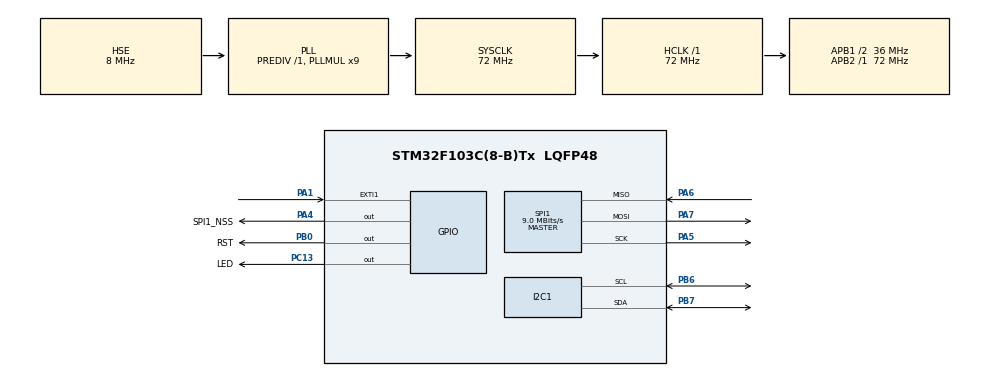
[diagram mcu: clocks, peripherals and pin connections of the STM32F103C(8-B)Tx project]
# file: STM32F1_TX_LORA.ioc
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Mcu.Family=STM32F1
Mcu.Name=STM32F103C(8-B)Tx
Mcu.Package=LQFP48
NVIC.EXTI1_IRQn=true\:0\:0\:false\:false\:true\:true\:true\:true
NVIC.PriorityGroup=NVIC_PRIORITYGROUP_4
PA1.GPIO_PuPd=GPIO_PULLUP
PA1.Signal=GPXTI1
PA13.Mode=Serial_Wire
PA13.Signal=SYS_JTMS-SWDIO
PA14.Mode=Serial_Wire
PA14.Signal=SYS_JTCK-SWCLK
PA4.GPIO_Label=SPI1_NSS
PA4.GPIO_PuPd=GPIO_NOPULL
PA4.PinState=GPIO_PIN_RESET
PA4.Signal=GPIO_Output
PA5.Mode=Full_Duplex_Master
PA5.Signal=SPI1_SCK
PA6.Mode=Full_Duplex_Master
PA6.Signal=SPI1_MISO
PA7.Mode=Full_Duplex_Master
PA7.Signal=SPI1_MOSI
PB0.GPIO_Label=RST
PB0.GPIO_PuPd=GPIO_NOPULL
PB0.PinState=GPIO_PIN_RESET
PB0.Signal=GPIO_Output
PB6.Mode=I2C
PB6.Signal=I2C1_SCL
PB7.Mode=I2C
PB7.Signal=I2C1_SDA
PC13-TAMPER-RTC.GPIO_Label=LED
PC13-TAMPER-RTC.GPIO_PuPd=GPIO_PULLUP
PC13-TAMPER-RTC.Signal=GPIO_Output
PD0-OSC_IN.Mode=HSE-External-Oscillator
PD0-OSC_IN.Signal=RCC_OSC_IN
PD1-OSC_OUT.Mode=HSE-External-Oscillator
PD1-OSC_OUT.Signal=RCC_OSC_OUT
ProjectManager.HeapSize=0x200
ProjectManager.StackSize=0x400
ProjectManager.TargetToolchain=STM32CubeIDE
RCC.AHBFreq_Value=72000000
RCC.APB1CLKDivider=RCC_HCLK_DIV2
RCC.APB1Freq_Value=36000000
RCC.APB1TimFreq_Value=72000000
RCC.APB2Freq_Value=72000000
RCC.APB2TimFreq_Value=72000000
RCC.HCLKFreq_Value=72000000
RCC.PLLMUL=RCC_PLL_MUL9
RCC.PLLSourceVirtual=RCC_PLLSOURCE_HSE
RCC.SYSCLKFreq_VALUE=72000000
RCC.SYSCLKSource=RCC_SYSCLKSOURCE_PLLCLK
RCC.USBFreq_Value=72000000
SPI1.BaudRatePrescaler=SPI_BAUDRATEPRESCALER_8
SPI1.CalculateBaudRate=9.0 MBits/s
SPI1.Direction=SPI_DIRECTION_2LINES
SPI1.Mode=SPI_MODE_MASTER
SPI1.VirtualType=VM_MASTER
board=custom

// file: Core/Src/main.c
/* USER CODE BEGIN Header */
/**
  ******************************************************************************
  * @file           : main.c
  * @brief          : Main program body
  ******************************************************************************
  * @attention
  *
  * Copyright (c) 2026 STMicroelectronics.
  * All rights reserved.
  *
  * This software is licensed under terms that can be found in the LICENSE file
  * in the root directory of this software component.
  * If no LICENSE file comes with this software, it is provided AS-IS.
  *
  ******************************************************************************
  */
/* USER CODE END Header */
#include <stdio.h>
#include <string.h>

#include "main.h"
#include "i2c-lcd.h"
#include "LoRa.h"

I2C_HandleTypeDef hi2c1;

SPI_HandleTypeDef hspi1;

/* USER CODE BEGIN PV */

LoRa myLoRa;
uint32_t last_send_tick = 0;
uint32_t send_count = 0;

/* USER CODE END PV */

void SystemClock_Config(void);
static void MX_GPIO_Init(void);
static void MX_SPI1_Init(void);
static void MX_I2C1_Init(void);

int main(void)
{

  /* MCU Configuration--------------------------------------------------------*/

  /* Reset of all peripherals, Initializes the Flash interface and the Systick. */
  HAL_Init();

  /* Configure the system clock */
  SystemClock_Config();

  /* Initialize all configured peripherals */
  MX_GPIO_Init();
  MX_SPI1_Init();
  MX_I2C1_Init();

  lcd_init();

  /* Dòng 1 LCD: tiêu đề cố định */
  lcd_goto_XY(1, 0);
  lcd_send_string("===== TX_LORA =====");

  /* USER CODE BEGIN 2 */

  myLoRa = newLoRa();
  myLoRa.hSPIx                 = &hspi1;
  myLoRa.CS_port               = NSS_GPIO_Port;
  myLoRa.CS_pin                = NSS_Pin;
  myLoRa.reset_port            = RST_GPIO_Port;
  myLoRa.reset_pin             = RST_Pin;
  myLoRa.DIO0_port             = DIO0_GPIO_Port;
  myLoRa.DIO0_pin              = DIO0_Pin;

  myLoRa.frequency             = 433;
  myLoRa.spredingFactor        = SF_7;
  myLoRa.bandWidth             = BW_125KHz;
  myLoRa.crcRate               = CR_4_5;
  myLoRa.power                 = POWER_20db;          // Công suất max
  myLoRa.overCurrentProtection = 120;
  myLoRa.preamble              = 10;

  /* Reset phần cứng module LoRa */
  LoRa_reset(&myLoRa);

  /* Khởi tạo LoRa, hiển thị trạng thái lên dòng 2 LCD */
  lcd_goto_XY(2, 0);
  while (LoRa_init(&myLoRa) != LORA_OK)
  {
    lcd_send_string("LoRa INIT FAIL!   ");
  }
  lcd_send_string("LoRa INIT OK! ");
  LoRa_setSyncWord(&myLoRa, 0x12); // Đảm bảo SyncWord của 2 mạch giống hệt nhau

  // Bật AGC
  LoRa_write(&myLoRa, 0x26, 0x04);

  /* USER CODE END 2 */

  /* Infinite loop */
  while (1)
  {
	  if (HAL_GetTick() - last_send_tick >= 500)
	  {
		  last_send_tick = HAL_GetTick();
		  send_count++;

		  char msg_buffer[20];
		  sprintf(msg_buffer, "*%lu#", (unsigned long)send_count);

		  uint8_t tx_result = LoRa_transmit(&myLoRa, (uint8_t*)msg_buffer, strlen(msg_buffer), 2000);

		  if (tx_result == 1)
		  {
			  HAL_GPIO_TogglePin(GPIOC, GPIO_PIN_13);

			  lcd_goto_XY(1, 0);
			  char tx_lcd[20];
			  snprintf(tx_lcd, sizeof(tx_lcd), "TX: %-12s", (char*)msg_buffer);
			  lcd_send_string(tx_lcd);

			  char lcd_line2[17];
			  snprintf(lcd_line2, sizeof(lcd_line2), "Cnt:%-5lu   OK  ", (unsigned long)send_count);
			  lcd_goto_XY(2, 0);
			  lcd_send_string(lcd_line2);
		  }
		  else
		  {
			  lcd_goto_XY(1, 0);
			  char tx_lcd[20];
			  snprintf(tx_lcd, sizeof(tx_lcd), "TX: %-12s", (char*)msg_buffer);
			  lcd_send_string(tx_lcd);

			  char lcd_line2[17];
			  snprintf(lcd_line2, sizeof(lcd_line2), "Cnt:%-5lu  FAIL ", (unsigned long)send_count);
			  lcd_goto_XY(2, 0);
			  lcd_send_string(lcd_line2);
		  }
	  }
  }
}

void SystemClock_Config(void)
{
  RCC_OscInitTypeDef RCC_OscInitStruct = {0};
  RCC_ClkInitTypeDef RCC_ClkInitStruct = {0};

  /** Initializes the RCC Oscillators according to the specified parameters
  * in the RCC_OscInitTypeDef structure.
  */
  RCC_OscInitStruct.OscillatorType = RCC_OSCILLATORTYPE_HSE;
  RCC_OscInitStruct.HSEState = RCC_HSE_ON;
  RCC_OscInitStruct.HSEPredivValue = RCC_HSE_PREDIV_DIV1;
  RCC_OscInitStruct.HSIState = RCC_HSI_ON;
  RCC_OscInitStruct.PLL.PLLState = RCC_PLL_ON;
  RCC_OscInitStruct.PLL.PLLSource = RCC_PLLSOURCE_HSE;
  RCC_OscInitStruct.PLL.PLLMUL = RCC_PLL_MUL9;
  if (HAL_RCC_OscConfig(&RCC_OscInitStruct) != HAL_OK)
  {
    Error_Handler();
  }

  /** Initializes the CPU, AHB and APB buses clocks
  */
  RCC_ClkInitStruct.ClockType = RCC_CLOCKTYPE_HCLK|RCC_CLOCKTYPE_SYSCLK
                              |RCC_CLOCKTYPE_PCLK1|RCC_CLOCKTYPE_PCLK2;
  RCC_ClkInitStruct.SYSCLKSource = RCC_SYSCLKSOURCE_PLLCLK;
  RCC_ClkInitStruct.AHBCLKDivider = RCC_SYSCLK_DIV1;
  RCC_ClkInitStruct.APB1CLKDivider = RCC_HCLK_DIV2;
  RCC_ClkInitStruct.APB2CLKDivider = RCC_HCLK_DIV1;

  if (HAL_RCC_ClockConfig(&RCC_ClkInitStruct, FLASH_LATENCY_2) != HAL_OK)
  {
    Error_Handler();
  }
}

static void MX_I2C1_Init(void)
{

  hi2c1.Instance = I2C1;
  hi2c1.Init.ClockSpeed = 100000;
  hi2c1.Init.DutyCycle = I2C_DUTYCYCLE_2;
  hi2c1.Init.OwnAddress1 = 0;
  hi2c1.Init.AddressingMode = I2C_ADDRESSINGMODE_7BIT;
  hi2c1.Init.DualAddressMode = I2C_DUALADDRESS_DISABLE;
  hi2c1.Init.OwnAddress2 = 0;
  hi2c1.Init.GeneralCallMode = I2C_GENERALCALL_DISABLE;
  hi2c1.Init.NoStretchMode = I2C_NOSTRETCH_DISABLE;
  if (HAL_I2C_Init(&hi2c1) != HAL_OK)
  {
    Error_Handler();
  }

}

static void MX_SPI1_Init(void)
{

  /* SPI1 parameter configuration*/
  hspi1.Instance = SPI1;
  hspi1.Init.Mode = SPI_MODE_MASTER;
  hspi1.Init.Direction = SPI_DIRECTION_2LINES;
  hspi1.Init.DataSize = SPI_DATASIZE_8BIT;
  hspi1.Init.CLKPolarity = SPI_POLARITY_LOW;
  hspi1.Init.CLKPhase = SPI_PHASE_1EDGE;
  hspi1.Init.NSS = SPI_NSS_SOFT;
  hspi1.Init.BaudRatePrescaler = SPI_BAUDRATEPRESCALER_8;
  hspi1.Init.FirstBit = SPI_FIRSTBIT_MSB;
  hspi1.Init.TIMode = SPI_TIMODE_DISABLE;
  hspi1.Init.CRCCalculation = SPI_CRCCALCULATION_DISABLE;
  hspi1.Init.CRCPolynomial = 10;
  if (HAL_SPI_Init(&hspi1) != HAL_OK)
  {
    Error_Handler();
  }

}

static void MX_GPIO_Init(void)
{
  GPIO_InitTypeDef GPIO_InitStruct = {0};

  /* GPIO Ports Clock Enable */
  __HAL_RCC_GPIOC_CLK_ENABLE();
  __HAL_RCC_GPIOD_CLK_ENABLE();
  __HAL_RCC_GPIOA_CLK_ENABLE();
  __HAL_RCC_GPIOB_CLK_ENABLE();

  /*Configure GPIO pin Output Level */
  HAL_GPIO_WritePin(LED_GPIO_Port, LED_Pin, GPIO_PIN_RESET);

  /*Configure GPIO pin Output Level */
  HAL_GPIO_WritePin(NSS_GPIO_Port, NSS_Pin, GPIO_PIN_SET);

  /*Configure GPIO pin Output Level */
  HAL_GPIO_WritePin(RST_GPIO_Port, RST_Pin, GPIO_PIN_SET);

  /*Configure GPIO pin : LED_Pin */
  GPIO_InitStruct.Pin = LED_Pin;
  GPIO_InitStruct.Mode = GPIO_MODE_OUTPUT_PP;
  GPIO_InitStruct.Pull = GPIO_PULLUP;
  GPIO_InitStruct.Speed = GPIO_SPEED_FREQ_LOW;
  HAL_GPIO_Init(LED_GPIO_Port, &GPIO_InitStruct);

  /*Configure GPIO pin : PA1 */
  GPIO_InitStruct.Pin = GPIO_PIN_1;
  GPIO_InitStruct.Mode = GPIO_MODE_IT_RISING;
  GPIO_InitStruct.Pull = GPIO_PULLUP;
  HAL_GPIO_Init(GPIOA, &GPIO_InitStruct);

  /*Configure GPIO pin : NSS_Pin */
  GPIO_InitStruct.Pin = NSS_Pin;
  GPIO_InitStruct.Mode = GPIO_MODE_OUTPUT_PP;
  GPIO_InitStruct.Pull = GPIO_NOPULL;
  GPIO_InitStruct.Speed = GPIO_SPEED_FREQ_LOW;
  HAL_GPIO_Init(NSS_GPIO_Port, &GPIO_InitStruct);

  /*Configure GPIO pin : RST_Pin */
  GPIO_InitStruct.Pin = RST_Pin;
  GPIO_InitStruct.Mode = GPIO_MODE_OUTPUT_PP;
  GPIO_InitStruct.Pull = GPIO_NOPULL;
  GPIO_InitStruct.Speed = GPIO_SPEED_FREQ_LOW;
  HAL_GPIO_Init(RST_GPIO_Port, &GPIO_InitStruct);

  /* EXTI interrupt init*/
  HAL_NVIC_SetPriority(EXTI1_IRQn, 0, 0);
  HAL_NVIC_EnableIRQ(EXTI1_IRQn);

}

void Error_Handler(void)
{
  __disable_irq();
  while (1)
  {
  }
}
